# ET6801 register map
Vendor: ETMCU Inc.; File version: v0.0.1
CPU: CM7 r2p1, little endian, MPU, FPU, I-cache, D-cache, ITCM, DTCM, 4 interrupt priority bits
Registers are 32-bit, read-write, reset 0x0 unless marked. A register's access mark holds for its fields unless they carry their own. Offsets are from the block's base; [hi:lo] are bit positions; {n}, {i} and the like mark numbered series; <NAME> marks a mode.

## CRG — Provide an overview of the purpose and functionality of the peripheral: crg_cfg
Base 0x4040C000
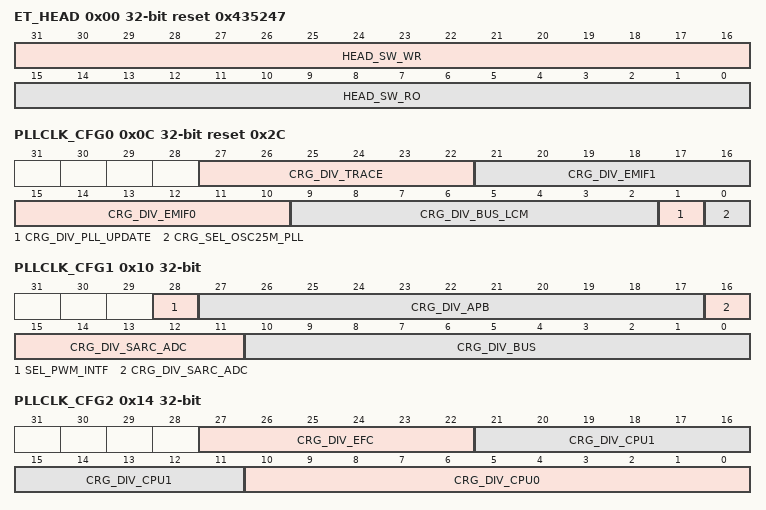
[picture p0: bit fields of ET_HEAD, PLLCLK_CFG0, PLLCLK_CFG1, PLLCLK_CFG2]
0x00 ET_HEAD reset 0x435247
  [31:16] HEAD_SW_WR — 软件测试读写寄存器，硬件无访问
  [15:0] HEAD_SW_RO ro — 软件只读上报寄存器，硬件无访问,CRG的ASICII 码表示
0x04 OSC25M_SEL
  [0] CRG_OSC25M_SEL — OSC25M时钟源选择信号： 1'b0：时钟源osc0_25m； 1'b1：时钟源osc1_25m；
0x08 PLLREF_CFG reset 0x2
  [2:0] CRG_PLL_REF_SEL — PLL参考时钟源选择信号： bit2: 默认0 1'b0：x025m和osc0/1_25m经过选择后的信号； 1'b1：pad_osc25m； bit1: 默认1 1'b0：x025m和osc025m经过选择后的信号； 1'b1：内部25m时钟源osc1_25m； bit0: 默认0 1'b0：时钟源xo25m； 1'b1：内部25m时钟源osc0_25m；
0x0C PLLCLK_CFG0 reset 0x2C
  [27:22] CRG_DIV_TRACE — Clk_bus到coresight工作时钟的分频系数 ， 6'd0：1分频 6'd1：2分频 6'd3：4分频 6'd5: 6 分频 6'd7：8分频 其他：正常使用时不使用该配置范围； 此配置值在"cfg_crg_div_pll_updata为1"且"bus时钟下计数到cfg_crg_div_bus_lcm值"时才更新；
  [21:16] CRG_DIV_EMIF1 — Clk_bus到emif1工作时钟的分频系数 ， 6'd0：1分频 6'd1：2分频 6'd2：3分频 6'd3：4分频 其他：正常使用时不使用该配置范围； 此配置值在"cfg_crg_div_pll_updata为1"且"bus时钟下计数到cfg_crg_div_bus_lcm值"时才更新；
  [15:10] CRG_DIV_EMIF0 — Clk_bus到emif0工作时钟的分频系数 ， 6'd0：1分频 6'd1：2分频 6'd2：3分频 6'd3：4分频 其他：正常使用时不使用该配置范围； 此配置值在"cfg_crg_div_pll_updata为1"且"bus时钟下计数到cfg_crg_div_bus_lcm值"时才更新；
  [9:2] CRG_DIV_BUS_LCM — bus_clk时钟源下各时钟（cpu0/1\cpu_apb0/1\apb\efc_flash\adc\emif\coresight）分频系数less common multipler（最小公倍数）配置，默认配置值+1 此配置默认为8'd11， 此配置值在"cfg_crg_div_pll_updata为1"且"bus时钟下计数到cfg_crg_div_bus_lcm值"时才更新；
  [1] CRG_DIV_PLL_UPDATE — PLL时钟分频系数更新指示信号 1'd0：不更新系数 1'd1：更新系数
  [0] CRG_SEL_OSC25M_PLL — OSC25M与PLL无毛刺切换的时钟选择信号： 1'd0: 选择osc25m 1'd1: 选择PLL 输出时钟 具体切换配置见CRG配置流程文档
0x10 PLLCLK_CFG1
  [28] SEL_PWM_INTF — pwm_interface接口时钟选择 1'b0:clk_bus 1'b1:clk_sys 400M
  [27:17] CRG_DIV_APB — Clk_bus到APB总线工作时钟分频系数 11'd0：1分频 11'd1：2分频 11'd3：4分频 11'd7：8分频 其他：正常使用时不使用该配置范围；当BUS时钟为200M时，配置为2分频，APB的时钟为100M 此配置值在"cfg_crg_div_pll_updata为1时才更新；
  [16:11] CRG_DIV_SARC_ADC — Clk_bus到到sarc adc工作时钟的分频系数 6'd0：1分频 6'd1：2分频 6'd2：3分频 6'd3：4分频 6'd4：5分频 6'd5-6'd63：正常使用时不使用该配置范围；当BUS时钟为200M时，配置为3分频，adc的时钟为66.6M 此配置值在"cfg_crg_div_pll_updata为1时才更新；
  [10:0] CRG_DIV_BUS — BUS总线的工作时钟分频系数 11'd0~11d'7：分别对应1分频~8分频 其他：正常使用时不使用该配置范围；pll为600M配置3分频，BUS的时钟为200M 其他：正常使用时不使用该配置范围； 此配置值在"cfg_crg_div_pll_updata为1时才更新；
0x14 PLLCLK_CFG2
  [27:22] CRG_DIV_EFC — Clk_bus到Efc flash工作时钟的分频系数 ， 6'd0：1分频 6'd1：2分频 6'd3：4分频 6'd5: 6 分频 6'd7：8分频 其他：正常使用时不使用该配置范围；当BUS时钟为200M时，配置为6分频，EFC FLASH的时钟为33.3M 此配置值在"cfg_crg_div_pll_updata为1"时才更新；
  [21:11] CRG_DIV_CPU1 — CPU1工作时钟分频系数， 11'd0~11d'7：分别对应1分频~8分频 6'd8-6'd63：正常使用时不使用该配置范围； PLL FOUT为600M
  [10:0] CRG_DIV_CPU0 — CPU0工作时钟分频系数， 11'd0~11d'7：分别对应1分频~8分频 6'd8-6'd63：正常使用时不使用该配置范围； PLL FOUT为600M时，配置为2分频 此配置值在"cfg_crg_div_pll_updata为1时才更新；
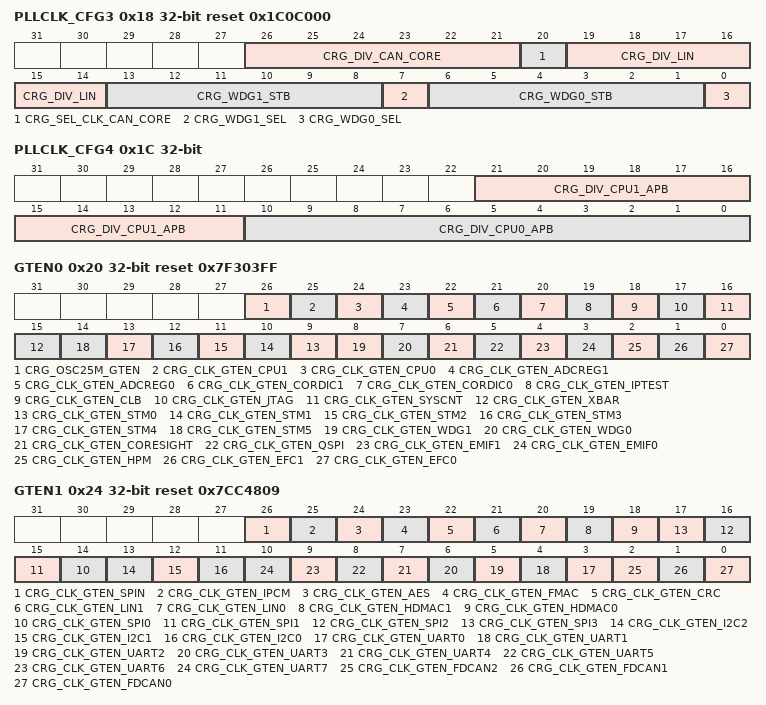
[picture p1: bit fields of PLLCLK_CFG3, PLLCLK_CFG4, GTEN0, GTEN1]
0x18 PLLCLK_CFG3 reset 0x1C0C000
  [26:21] CRG_DIV_CAN_CORE — Can core时钟分频系数 6'd4：5分频,由400M时钟分频到80M 6'd9：10分频,由600M时钟分频到60M 6'd14:：15分频，由600M时钟分频到40M(默认) 到60M 其他：正常使用时不使用该配置范围 此配置值在"cfg_crg_div_pll_updata为1"时才更新；
  [20] CRG_SEL_CLK_CAN_CORE — Can core时钟sel信号 1'd0：选择PLL的输出时钟 1'd1：选择pad输入的auxclk 默认选择PLL输出的400M时钟，静态切换
  [19:14] CRG_DIV_LIN — CLK_APB到LIN工作时钟分频系数 6'd0：1分频 6'd1：2分频 6'd3：4分频 6'd5：6分频 6'd7：8分频 6'd8-6'd63：正常使用时不使用该配置范围 ，默认4分频 此配置值在"cfg_crg_div_pll_updata为1时才更新；
  [13:8] CRG_WDG1_STB — wdg1的分频使能（clken），当wdg1选择APB时钟时， 支持对APB时钟进行1~64分频，作为数据使用， 6'd0：1分频使能 6'd1：2分频使能 6'd2：3分频使能 ...... 6'd63：64分频使能
  [7] CRG_WDG1_SEL — Wdg1时钟选择信号 1'd0：osc25m 1'd1：clk_apb1 默认选择osc25m_ana
  [6:1] CRG_WDG0_STB — wdg0的分频使能（clken），当wdg0选择APB时钟时， 支持对APB时钟进行1~64分频，作为数据使用， 6'd0：1分频使能 6'd1：2分频使能 6'd2：3分频使能 ...... 6'd63：64分频使能
  [0] CRG_WDG0_SEL — Wdg0时钟选择信号 1'd0：osc25m 1'd1：clk_apb1 默认选择osc25m_ana
0x1C PLLCLK_CFG4
  [21:11] CRG_DIV_CPU1_APB — CLK_CPU1到CPU1 APB接口配置时钟分频系数 11'd0~11d'7：分别对应1分频~8分频 11'd8-11'd2047：正常使用时不使用该配置范围；
  [10:0] CRG_DIV_CPU0_APB — CLK_CPU0到CPU0 APB接口配置时钟分频系数 11'd0~11d'7：分别对应1分频~8分频 11'd8-11'd2047：正常使用时不使用该配置范围；
0x20 GTEN0 reset 0x7F303FF
  [26] CRG_OSC25M_GTEN — OSC25M （osc0_25m_ana和osc1_25m_ana选择后的时钟）的时钟门控： 1：打开OSC25M时钟，0：关闭OSC25M时钟 在BootRom流程中，系统时钟切换到PLL时钟后，需要对osc25M时钟trim，trim时要关闭OSC25M时钟。 在BootRom流程中，系统时钟切换到PLL时钟后，关闭OSC0_25M与OSC1_25M选择后的时钟门控 此OSC25M时钟作用范围：EFUSE，JTAG_AUTH鉴权，WDT，SYSCNT，CPU, CRG展宽使用的OSC25M工作时钟
  [25] CRG_CLK_GTEN_CPU1 — cpu1的时钟门控配置 ，1表示开时钟，0表示关时钟
  [24] CRG_CLK_GTEN_CPU0 — cpu0的时钟门控配置 ，1表示开时钟，0表示关时钟
  [23] CRG_CLK_GTEN_ADCREG1 — cpu1 adcreg的时钟门控配置，1表示开时钟，0表示关时钟
  [22] CRG_CLK_GTEN_ADCREG0 — cpu0 adcreg的时钟门控配置，1表示开时钟，0表示关时钟
  [21] CRG_CLK_GTEN_CORDIC1 — cpu1 cordic的时钟门控配置，1表示开时钟，0表示关时钟
  [20] CRG_CLK_GTEN_CORDIC0 — cpu0 cordic的时钟门控配置，1表示开时钟，0表示关时钟
  [19] CRG_CLK_GTEN_IPTEST — IPTEST的时钟门控配置，1表示开时钟，0表示关时钟
  [18] CRG_CLK_GTEN_CLB — CLB的时钟门控配置，1表示开时钟，0表示关时钟
  [17] CRG_CLK_GTEN_JTAG — JTAG的时钟门控配置，1表示开时钟，0表示关时钟
  [16] CRG_CLK_GTEN_SYSCNT — SYSCNT的时钟门控配置，1表示开时钟，0表示关时钟
  [15] CRG_CLK_GTEN_XBAR — XBAR的时钟门控配置，1表示开时钟，0表示关时钟
  [n+9] CRG_CLK_GTEN_STM{n} (n=0..5) — STM{n}时钟门控配置，1表示开时钟，0表示关时钟
  [8] CRG_CLK_GTEN_WDG1 — WDG1的时钟门控配置，1表示开时钟，0表示关时钟
  [7] CRG_CLK_GTEN_WDG0 — WDG0的时钟门控配置，1表示开时钟，0表示关时钟
  [6] CRG_CLK_GTEN_CORESIGHT — CORE_SIGHT的时钟门控配置，1表示开时钟，0表示关时钟
  [5] CRG_CLK_GTEN_QSPI — QSPI的时钟门控配置，1表示开时钟，0表示关时钟
  [4] CRG_CLK_GTEN_EMIF1 — EMIF1的时钟门控配置，1表示开时钟，0表示关时钟
  [3] CRG_CLK_GTEN_EMIF0 — EMIF0的时钟门控配置，1表示开时钟，0表示关时钟
  [2] CRG_CLK_GTEN_HPM — HPM的时钟门控配置，1表示开时钟，0表示关时钟
  [1] CRG_CLK_GTEN_EFC1 — EFC1的时钟门控配置，1表示开时钟，0表示关时钟
  [0] CRG_CLK_GTEN_EFC0 — EFC0的时钟门控配置，1表示开时钟，0表示关时钟
0x24 GTEN1 reset 0x7CC4809
  [26] CRG_CLK_GTEN_SPIN — SPIN_LOCK的时钟门控配置，1表示开时钟，0表示关时钟
  [25] CRG_CLK_GTEN_IPCM — IPCM的时钟门控配置，1表示开时钟，0表示关时钟
  [24] CRG_CLK_GTEN_AES — AES的时钟门控配置，1表示开时钟，0表示关时钟
  [23] CRG_CLK_GTEN_FMAC — FMAC的时钟门控配置，1表示开时钟，0表示关时钟
  [22] CRG_CLK_GTEN_CRC — CRC的时钟门控配置，1表示开时钟，0表示关时钟
  [21] CRG_CLK_GTEN_LIN1 — LIN1的时钟门控配置，1表示开时钟，0表示关时钟
  [20] CRG_CLK_GTEN_LIN0 — LIN0的时钟门控配置，1表示开时钟，0表示关时钟
  [19] CRG_CLK_GTEN_HDMAC1 — HDMAC1的时钟门控配置，1表示开时钟，0表示关时钟
  [18] CRG_CLK_GTEN_HDMAC0 — HDMAC0的时钟门控配置，1表示开时钟，0表示关时钟
  [n+14] CRG_CLK_GTEN_SPI{n} (n=0..3) — SPI{n}的时钟门控配置，1表示开时钟，0表示关时钟
  [13] CRG_CLK_GTEN_I2C2 — I2C2(PMBUS)的时钟门控配置，1表示开时钟，0表示关时钟
  [12] CRG_CLK_GTEN_I2C1 — I2C1的时钟门控配置，1表示开时钟，0表示关时钟
  [11] CRG_CLK_GTEN_I2C0 — I2C0的时钟门控配置，1表示开时钟，0表示关时钟
  [n+3] CRG_CLK_GTEN_UART{n} (n=0..7) — UART{n}的时钟门控配置，1表示开时钟，0表示关时钟
  [2] CRG_CLK_GTEN_FDCAN2 — FDCAN2的时钟门控配置，1表示开时钟，0表示关时钟
  [1] CRG_CLK_GTEN_FDCAN1 — FDCAN1的时钟门控配置，1表示开时钟，0表示关时钟
  [0] CRG_CLK_GTEN_FDCAN0 — FDCAN0的时钟门控配置，1表示开时钟，0表示关时钟
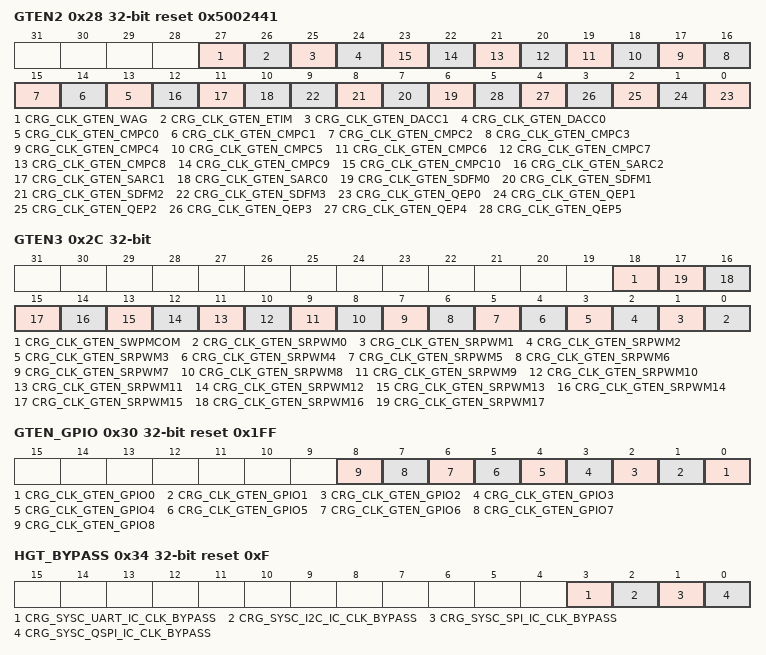
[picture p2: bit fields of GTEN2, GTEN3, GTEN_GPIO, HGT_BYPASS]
0x28 GTEN2 reset 0x5002441
  [27] CRG_CLK_GTEN_WAG — WAG的时钟门控配置，1表示开时钟，0表示关时钟
  [26] CRG_CLK_GTEN_ETIM — ETIM的时钟门控配置，1表示开时钟，0表示关时钟
  [25] CRG_CLK_GTEN_DACC1 — DACC1的时钟门控配置，1表示开时钟，0表示关时钟
  [24] CRG_CLK_GTEN_DACC0 — DACC0的时钟门控配置，1表示开时钟，0表示关时钟
  [n+13] CRG_CLK_GTEN_CMPC{n} (n=0..10) — CMPC{n}的时钟门控配置，1表示开时钟，0表示关时钟
  [12] CRG_CLK_GTEN_SARC2 — SARC2的时钟门控配置，1表示开时钟，0表示关时钟
  [11] CRG_CLK_GTEN_SARC1 — SARC1的时钟门控配置，1表示开时钟，0表示关时钟
  [10] CRG_CLK_GTEN_SARC0 — SARC0的时钟门控配置，1表示开时钟，0表示关时钟
  [n+6] CRG_CLK_GTEN_SDFM{n} (n=0..3) — SDFM{n}的时钟门控配置，1表示开时钟，0表示关时钟
  [n] CRG_CLK_GTEN_QEP{n} (n=0..5) — QEP{n}的时钟门控配置，1表示开时钟，0表示关时钟
0x2C GTEN3
  [18] CRG_CLK_GTEN_SWPMCOM — SPWM_COM的时钟门控配置，1表示开时钟，0表示关时钟
  [n] CRG_CLK_GTEN_SRPWM{n} (n=0..17) — SRPWM{n}的时钟门控配置，1表示开时钟，0表示关时钟
0x30 GTEN_GPIO reset 0x1FF
  [n] CRG_CLK_GTEN_GPIO{n} (n=0..8) — GPIO{n}的时钟门控配置，1表示开时钟，0表示关时钟
0x34 HGT_BYPASS reset 0xF
  [3] CRG_SYSC_UART_IC_CLK_BYPASS — uart硬件门控的bypass控制，6个 uart统一控制。1表示bypass硬件门控
  [2] CRG_SYSC_I2C_IC_CLK_BYPASS — I2c硬件门控的bypass控制，3个i2c统一控制。1表示bypass硬件门控
  [1] CRG_SYSC_SPI_IC_CLK_BYPASS — spi硬件门控的bypass控制。4个spi统一控制。1表示bypass硬件门控
  [0] CRG_SYSC_QSPI_IC_CLK_BYPASS — qspi硬件门控的bypass控制。1表示bypass硬件门控
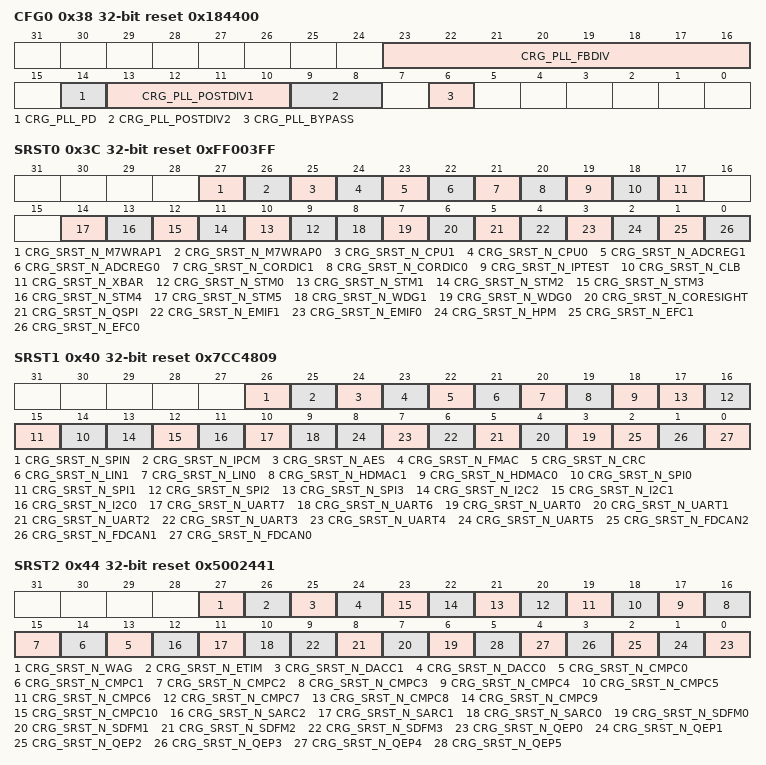
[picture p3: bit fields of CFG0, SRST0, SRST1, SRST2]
0x38 CFG0 reset 0x184400
  [23:16] CRG_PLL_FBDIV — PLL Feedback divide value。represent M M = M7*128+M6*64+M5*32+M4*16+M3*8+M2*4+M1*2+M0*1 defalt value = 24 clk_out = XIN * M/N/NO 1Mhz <= XIN/N <= 50Mhz 500Mhz <= clo_out * NO <= 1500 Mhz M >=2 , N >= 1
  [14] CRG_PLL_PD — Power down for PLL 0：work； 1：power down；
  [13:10] CRG_PLL_POSTDIV1 — PLL post divide 1 , represent N = N3*8+N2*4+N1*2+N0*1 Total post divide is POSTDIV1*POSTDIV2
  [9:8] CRG_PLL_POSTDIV2 — PLL post divide 2 , represent OD, NO=2^OD0+OD1*2 Total post divide is POSTDIV1*POSTDIV2
  [6] CRG_PLL_BYPASS — fref是否需要bypass到foutpostdiv。 0：pll正常输出； 1：fref bypass到foutpostdiv；
0x3C SRST0 reset 0xFF003FF
  [27] CRG_SRST_N_M7WRAP1 — m7_wrap1模块软复位配置，1表示不复位，0表示复位
  [26] CRG_SRST_N_M7WRAP0 — m7_wrap0模块软复位配置，1表示不复位，0表示复位
  [25] CRG_SRST_N_CPU1 — cpu1模块软复位配置，1表示不复位，0表示复位
  [24] CRG_SRST_N_CPU0 — cpu0模块软复位配置，1表示不复位，0表示复位
  [23] CRG_SRST_N_ADCREG1 — cpu1_adcreg模块软复位配置，1表示不复位，0表示复位
  [22] CRG_SRST_N_ADCREG0 — cpu0_adcreg模块软复位配置，1表示不复位，0表示复位
  [21] CRG_SRST_N_CORDIC1 — cpu1_cordic模块软复位配置，1表示不复位，0表示复位
  [20] CRG_SRST_N_CORDIC0 — cpu0_cordic模块软复位配置，1表示不复位，0表示复位
  [19] CRG_SRST_N_IPTEST — IPTEST的模块软复位配置，1表示不复位，0表示复位
  [18] CRG_SRST_N_CLB — CLB的模块软复位配置，1表示不复位，0表示复位
  [17] CRG_SRST_N_XBAR — XBAR的模块软复位配置，1表示不复位，0表示复位
  [n+9] CRG_SRST_N_STM{n} (n=0..5) — STM{n}模块软复位配置，1表示不复位，0表示复位
  [8] CRG_SRST_N_WDG1 — WDG1的模块软复位配置，1表示不复位，0表示复位
  [7] CRG_SRST_N_WDG0 — WDG0的模块软复位配置，1表示不复位，0表示复位
  [6] CRG_SRST_N_CORESIGHT — CORE_SIGHT的模块软复位配置，1表示不复位，0表示复位
  [5] CRG_SRST_N_QSPI — QSPI的模块软复位配置，1表示不复位，0表示复位
  [4] CRG_SRST_N_EMIF1 — EMIF1的模块软复位配置，1表示不复位，0表示复位
  [3] CRG_SRST_N_EMIF0 — EMIF0的模块软复位配置，1表示不复位，0表示复位
  [2] CRG_SRST_N_HPM — HPM的模块软复位配置，1表示不复位，0表示复位
  [1] CRG_SRST_N_EFC1 — EFC1的模块软复位配置，1表示不复位，0表示复位
  [0] CRG_SRST_N_EFC0 — EFC0的模块软复位配置，1表示不复位，0表示复位
0x40 SRST1 reset 0x7CC4809
  [26] CRG_SRST_N_SPIN — SPIN_LOCK的模块软复位配置，1表示不复位，0表示复位
  [25] CRG_SRST_N_IPCM — IPCM的模块软复位配置，1表示不复位，0表示复位
  [24] CRG_SRST_N_AES — AES的模块软复位配置，1表示不复位，0表示复位
  [23] CRG_SRST_N_FMAC — FMAC的模块软复位配置，1表示不复位，0表示复位
  [22] CRG_SRST_N_CRC — CRC的模块软复位配置，1表示不复位，0表示复位
  [21] CRG_SRST_N_LIN1 — LIN1的模块软复位配置，1表示不复位，0表示复位
  [20] CRG_SRST_N_LIN0 — LIN0的模块软复位配置，1表示不复位，0表示复位
  [19] CRG_SRST_N_HDMAC1 — HDMAC1的模块软复位配置，1表示不复位，0表示复位
  [18] CRG_SRST_N_HDMAC0 — HDMAC0的模块软复位配置，1表示不复位，0表示复位
  [n+14] CRG_SRST_N_SPI{n} (n=0..3) — SPI{n}的模块软复位配置，1表示不复位，0表示复位
  [13] CRG_SRST_N_I2C2 — I2C2(PMBUS)的模块软复位配置，1表示不复位，0表示复位
  [12] CRG_SRST_N_I2C1 — I2C1的模块软复位配置，1表示不复位，0表示复位
  [11] CRG_SRST_N_I2C0 — I2C0的模块软复位配置，1表示不复位，0表示复位
  [10] CRG_SRST_N_UART7 — UART7模块软复位配置，1表示不复位，0表示复位
  [9] CRG_SRST_N_UART6 — UART6模块软复位配置，1表示不复位，0表示复位
  [n+3] CRG_SRST_N_UART{n} (n=0..5) — UART{n}的模块软复位配置，1表示不复位，0表示复位
  [2] CRG_SRST_N_FDCAN2 — FDCAN2的模块软复位配置，1表示不复位，0表示复位
  [1] CRG_SRST_N_FDCAN1 — FDCAN1的模块软复位配置，1表示不复位，0表示复位
  [0] CRG_SRST_N_FDCAN0 — FDCAN0的模块软复位配置，1表示不复位，0表示复位
0x44 SRST2 reset 0x5002441
  [27] CRG_SRST_N_WAG — WAG的模块软复位配置，1表示不复位，0表示复位
  [26] CRG_SRST_N_ETIM — ETIM的模块软复位配置，1表示不复位，0表示复位
  [25] CRG_SRST_N_DACC1 — DACC1的模块软复位配置，1表示不复位，0表示复位
  [24] CRG_SRST_N_DACC0 — DACC0的模块软复位配置，1表示不复位，0表示复位
  [n+13] CRG_SRST_N_CMPC{n} (n=0..10) — CMPC{n}的模块软复位配置，1表示不复位，0表示复位
  [12] CRG_SRST_N_SARC2 — SARC2的模块软复位配置，1表示不复位，0表示复位
  [11] CRG_SRST_N_SARC1 — SARC1的模块软复位配置，1表示不复位，0表示复位
  [10] CRG_SRST_N_SARC0 — SARC0的模块软复位配置，1表示不复位，0表示复位
  [n+6] CRG_SRST_N_SDFM{n} (n=0..3) — SDFM{n}的模块软复位配置，1表示不复位，0表示复位
  [n] CRG_SRST_N_QEP{n} (n=0..5) — QEP{n}的模块软复位配置，1表示不复位，0表示复位
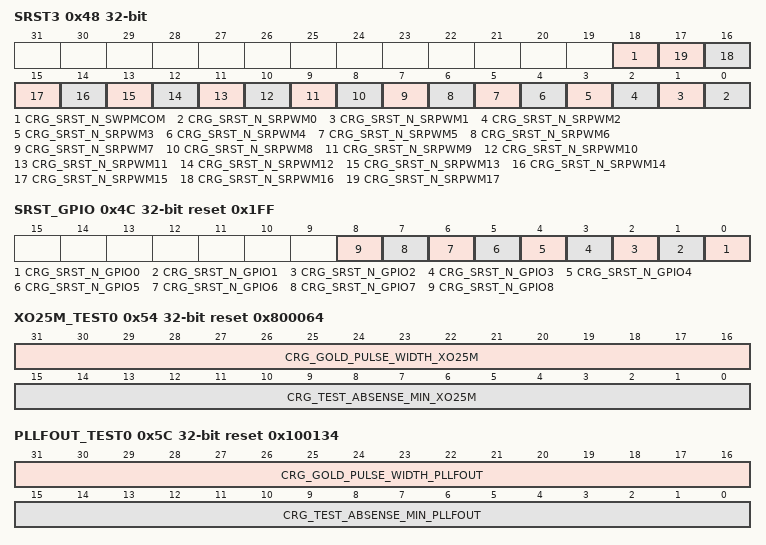
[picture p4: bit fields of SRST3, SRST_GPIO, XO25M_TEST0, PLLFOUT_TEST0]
0x48 SRST3
  [18] CRG_SRST_N_SWPMCOM — SPWM_COM的模块软复位配置，1表示不复位，0表示复位
  [n] CRG_SRST_N_SRPWM{n} (n=0..17) — SRPWM{n}的模块软复位配置，1表示不复位，0表示复位
0x4C SRST_GPIO reset 0x1FF
  [n] CRG_SRST_N_GPIO{n} (n=0..8) — GPIO{n}的模块软复位配置，1表示不复位，0表示复位
0x50 CLK_TEST_EN reset 0x1
  [0] CRG_CLK_TEST_EN — 时钟检测使能信号，1表示使能时钟检测，0表示不使能； 默认打开时钟检测； 该en信号控制以下时钟检测功能模块： osc0_25mosc1_25m 时钟丢失检测， osc1_25mosc0_25m 时钟丢失检测， osc1_25mxo25m 时钟丢失检测， xo25mosc1_25m 时钟丢失检测， osc1_25mpll_fout 时钟丢失检测， 注意： 以上这些检测模块在配置参数修改前，必须先将该en信号关闭，参数配置修改完成后再打开该en信号。
0x54 XO25M_TEST0 reset 0x800064
  [31:16] CRG_GOLD_PULSE_WIDTH_XO25M — OSC25M时钟检测XO25M时钟。检测宽度配置 默认配置16'd128；
  [15:0] CRG_TEST_ABSENSE_MIN_XO25M — OSC25M时钟检测XO25M时钟。检测宽度内，最小时钟周期数配置。当计数小于该配置值时，上报时钟丢失告警 默认配置16'd100；
0x58 XO25M_TEST1 reset 0x9C
  [15:0] CRG_TEST_ABSENSE_MAX_XO25M — OSC25M时钟检测XO25M时钟。检测宽度内，最大时钟周期数配置。当计数大于该配置值时，上报时钟丢失告警 默认配置16'd156；
0x5C PLLFOUT_TEST0 reset 0x100134
  [31:16] CRG_GOLD_PULSE_WIDTH_PLLFOUT — OSC25M时钟检测PLLFOUT（PLL 输出的600M）时钟。检测宽度配置 默认配置16'd16
  [15:0] CRG_TEST_ABSENSE_MIN_PLLFOUT — OSC25M时钟检测PLLFOUT（PLL 输出的600M）时钟。检测宽度内，最小时钟周期数配置。当计数小于该配置值时，上报时钟丢失告警 默认配置8'd100；默认配置16'd308；
0x60 PLLFOUT_TEST1 reset 0x1CC
  [15:0] CRG_TEST_ABSENSE_MAX_PLLFOUT — OSC25M时钟检测PLL1FOUT（PLL 输出的600M）时钟。检测宽度内，最大时钟周期数配置。当计数大于该配置值时，上报时钟丢失告警 默认配置16'd460；
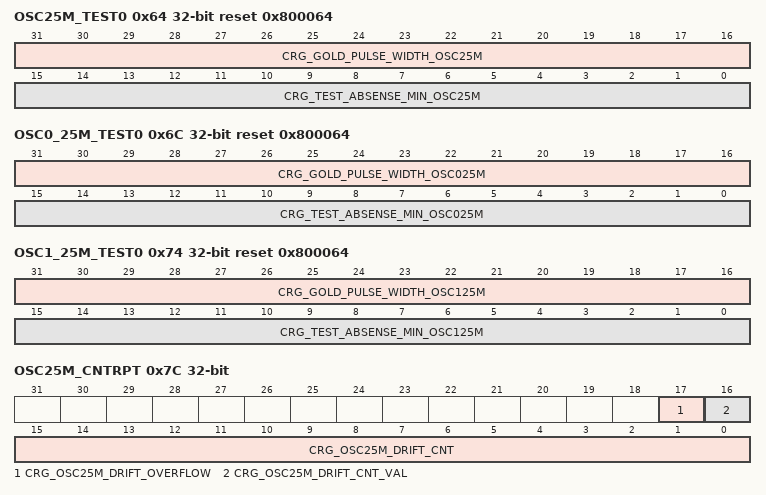
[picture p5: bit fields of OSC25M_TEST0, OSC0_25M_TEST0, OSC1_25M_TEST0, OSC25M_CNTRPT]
0x64 OSC25M_TEST0 reset 0x800064
  [31:16] CRG_GOLD_PULSE_WIDTH_OSC25M — XO25M时钟检测OSC1_25M时钟。检测宽度配置， 默认配置16'd128；
  [15:0] CRG_TEST_ABSENSE_MIN_OSC25M — XO25M时钟检测OSC25M时钟。检测宽度内，最小时钟周期数配置。当计数小于该配置值时，上报时钟丢失告警 默认配置16'd100；
0x68 OSC25M_TEST1 reset 0x9C
  [15:0] CRG_TEST_ABSENSE_MAX_OSC25M — XO25M时钟检测OSC1_25M时钟。检测宽度内，最大时钟周期数配置。当计数大于该配置值时，上报时钟丢失告警 默认配置16'd156；
0x6C OSC0_25M_TEST0 reset 0x800064
  [31:16] CRG_GOLD_PULSE_WIDTH_OSC025M — OSC1_25M时钟检测OSC0_25M时钟。检测宽度配置， 默认配置16'd128；
  [15:0] CRG_TEST_ABSENSE_MIN_OSC025M — OSC1_25M时钟检测OSC0_25M时钟。检测宽度内，最小时钟周期数配置。当计数小于该配置值时，上报时钟丢失告警 默认配置16'd100；
0x70 OSC0_25M_TEST1 reset 0x9C
  [15:0] CRG_TEST_ABSENSE_MAX_OSC025M — OSC1_25M时钟检测OSC0_25M时钟。检测宽度内，最大时钟周期数配置。当计数大于该配置值时，上报时钟丢失告警 默认配置16'd156；
0x74 OSC1_25M_TEST0 reset 0x800064
  [31:16] CRG_GOLD_PULSE_WIDTH_OSC125M — OSC0_25M时钟检测OSC1_25M时钟。检测宽度配置， 默认配置16'd128；
  [15:0] CRG_TEST_ABSENSE_MIN_OSC125M — XSC1_25M时钟检测OSC0_25M时钟。检测宽度内，最小时钟周期数配置。当计数小于该配置值时，上报时钟丢失告警 默认配置16'd100；
0x78 OSC1_25M_TEST1 reset 0x9C
  [15:0] CRG_TEST_ABSENSE_MAX_OSC125M — OSC0_25M时钟检测OSC1_25M时钟。检测宽度内，最大时钟周期数配置。当计数大于该配置值时，上报时钟丢失告警 默认配置16'd156；
0x7C OSC25M_CNTRPT ro
  [17] CRG_OSC25M_DRIFT_OVERFLOW — XO25M检查OSC25M频偏的计数值有效指示，为1表示计数溢出过。
  [16] CRG_OSC25M_DRIFT_CNT_VAL — XO25M检查OSC25M频偏的计数值有效指示，为1表示计数值有效
  [15:0] CRG_OSC25M_DRIFT_CNT — XO25M检查OSC25M频偏的计数值，31bit计数值； 当计数溢出时，该16bit保持最大值；
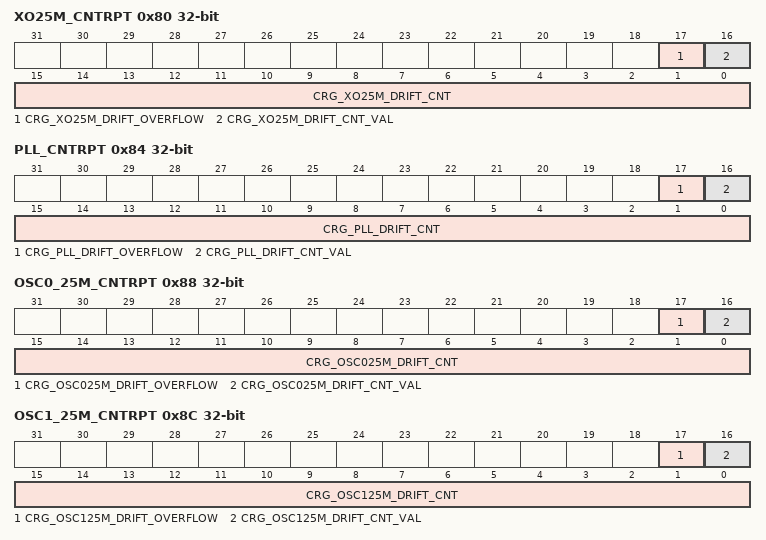
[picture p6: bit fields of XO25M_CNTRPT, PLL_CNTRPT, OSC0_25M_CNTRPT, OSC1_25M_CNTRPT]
0x80 XO25M_CNTRPT ro
  [17] CRG_XO25M_DRIFT_OVERFLOW — OSC25M检查XO25M频偏的计数值有效指示，为1表示计数溢出过。
  [16] CRG_XO25M_DRIFT_CNT_VAL — OSC25M检查XO25M频偏的计数值有效指示，为1表示计数值有效
  [15:0] CRG_XO25M_DRIFT_CNT — OSC25M检查XO25M频偏的计数值，31bit计数值； 当计数溢出时，该16bit保持最大值；
0x84 PLL_CNTRPT ro
  [17] CRG_PLL_DRIFT_OVERFLOW — OSC25M检查PLL频偏的计数值有效指示，为1表示计数溢出过。
  [16] CRG_PLL_DRIFT_CNT_VAL — OSC25M检查PLL频偏的计数值有效指示，为1表示计数值有效
  [15:0] CRG_PLL_DRIFT_CNT — OSC25M检查PLL频偏的计数值，31bit计数值； 当计数溢出时，该16bit保持最大值；
0x88 OSC0_25M_CNTRPT ro
  [17] CRG_OSC025M_DRIFT_OVERFLOW — OSC1_25M检查OSC0_25M频偏的计数值有效指示，为1表示计数溢出过。
  [16] CRG_OSC025M_DRIFT_CNT_VAL — OSC1_25M检查OSC0_25M频偏的计数值有效指示，为1表示计数值有效
  [15:0] CRG_OSC025M_DRIFT_CNT — OSC1_25M检查OSC0_25M频偏的计数值，31bit计数值； 当计数溢出时，该16bit保持最大值；
0x8C OSC1_25M_CNTRPT ro
  [17] CRG_OSC125M_DRIFT_OVERFLOW — OSC0_25M检查OSC1_25M频偏的计数值有效指示，为1表示计数溢出过。
  [16] CRG_OSC125M_DRIFT_CNT_VAL — OSC0_25M检查OSC1_25M频偏的计数值有效指示，为1表示计数值有效
  [15:0] CRG_OSC125M_DRIFT_CNT — OSC0_25M检查OSC1_25M频偏的计数值，31bit计数值； 当计数溢出时，该16bit保持最大值；
0x90 OSCCAL_EN
  [0] CRG_OSCCAL_EN — osc25m校正使能信号，用于启动osc25m校正
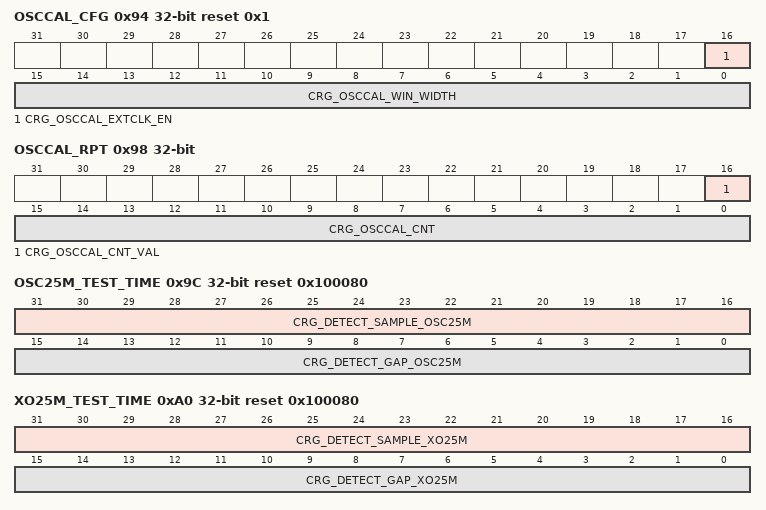
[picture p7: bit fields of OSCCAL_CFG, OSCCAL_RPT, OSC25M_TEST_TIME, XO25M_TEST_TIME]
0x94 OSCCAL_CFG reset 0x1
  [16] CRG_OSCCAL_EXTCLK_EN — osc25m校正时的高精度时钟选择。0表示选择xo32.768k，1表示选择io输入时钟
  [15:0] CRG_OSCCAL_WIN_WIDTH — osc25m校正计数窗口，高精度参考时钟的周期数配置，默认配置为2个周期 16'd0：1个周期； 16'd 1：2个周期； 16'd 2：3个周期； ......
0x98 OSCCAL_RPT ro
  [16] CRG_OSCCAL_CNT_VAL — osc25m校正计数有效指示信号，该信号为高时counter有效，读清零
  [15:0] CRG_OSCCAL_CNT — osc25m校正计数counter值
0x9C OSC25M_TEST_TIME reset 0x100080
  [31:16] CRG_DETECT_SAMPLE_OSC25M — XO25M时钟检测OSC1_25M时钟。检测采样点时间配置， 默认配置16'h10； 注意：如果用户需要修改此配置值，要求修改值必须大于16'h10；
  [15:0] CRG_DETECT_GAP_OSC25M — XO25M时钟检测OSC1_25M时钟。检测间隔配置， 默认配置16'h80； 注意：如果用户需要修改此配置值，要求修改值必须大于16'h80；
0xA0 XO25M_TEST_TIME reset 0x100080
  [31:16] CRG_DETECT_SAMPLE_XO25M — OSC1_25M时钟检测XO25M时钟。检测采样点时间配置， 默认配置16'h10； 注意：如果用户需要修改此配置值，要求修改值必须大于16'h10；
  [15:0] CRG_DETECT_GAP_XO25M — OSC1_25M时钟检测XO25M时钟。检测间隔配置， 默认配置16'h80； 注意：如果用户需要修改此配置值，要求修改值必须大于16'h80；
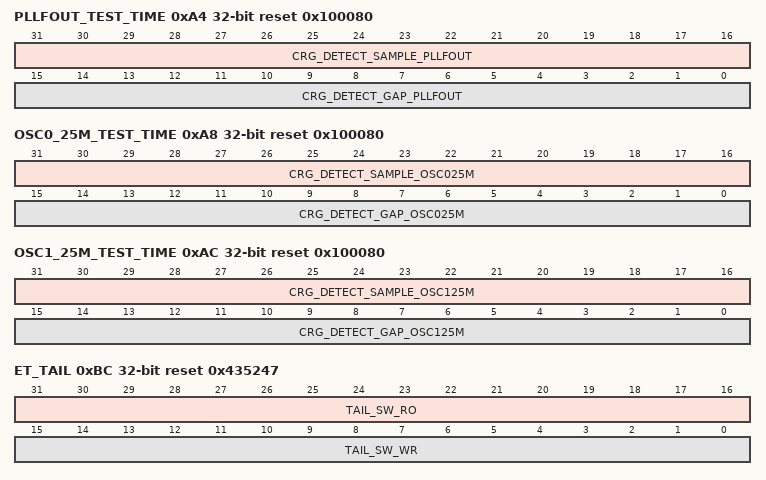
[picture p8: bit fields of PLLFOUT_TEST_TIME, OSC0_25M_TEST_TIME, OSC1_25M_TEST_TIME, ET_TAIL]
0xA4 PLLFOUT_TEST_TIME reset 0x100080
  [31:16] CRG_DETECT_SAMPLE_PLLFOUT — OSC25M时钟检测PLLFOUT时钟。检测采样点时间配置， 默认配置16'h10； 注意：如果用户需要修改此配置值，要求修改值必须大于16'h10；
  [15:0] CRG_DETECT_GAP_PLLFOUT — OSC25M时钟检测PLLFOUT时钟。检测间隔配置， 默认配置16'h80； 注意：如果用户需要修改此配置值，要求修改值必须大于16'h80；
0xA8 OSC0_25M_TEST_TIME reset 0x100080
  [31:16] CRG_DETECT_SAMPLE_OSC025M — OSC1_25M时钟检测OSC0_25M时钟。检测采样点时间配置， 默认配置16'h10； 注意：如果用户需要修改此配置值，要求修改值必须大于16'h10；
  [15:0] CRG_DETECT_GAP_OSC025M — OSC1_25M时钟检测OSC0_25M时钟。检测间隔配置， 默认配置16'h80； 注意：如果用户需要修改此配置值，要求修改值必须大于16'h80；
0xAC OSC1_25M_TEST_TIME reset 0x100080
  [31:16] CRG_DETECT_SAMPLE_OSC125M — OSC0_25M时钟检测OSC1_25M时钟。检测采样点时间配置， 默认配置16'h10； 注意：如果用户需要修改此配置值，要求修改值必须大于16'h10；
  [15:0] CRG_DETECT_GAP_OSC125M — OSC0_25M时钟检测OSC1_25M时钟。检测间隔配置， 默认配置16'h80； 注意：如果用户需要修改此配置值，要求修改值必须大于16'h80；
0xB0 DEBUG ro
  [31:0] CRG_DEBUG — Debug信号： Bit7-bit0： Ana_por_fg Osc25m_por Rstn_por Osc25m_hrstn Osc25m_grstn Osc25m_wdg0 Osc25m_wdg1 Osc25m_cpu0_grstn; Bit15-bit8： sysc_por_fg_rst_n Osc25m_cpu1_grstn; ioc_flt_rstn Ioc_presetn Hrstn_sources Hrstn_chip Rstn_crg Rstn_hrd; Bit27-bit16: Osc25m_bps_n, Por_bps_n, stb_wdg1_clken, stb_wdg0_clken, dft_pll_bypass, dft_sel_osc25m_pll hrstn_fg, a2d_por1p1, A2d_pmu_vdda_ok, Crg_dac_latch_output, 1'd0, 1'd0, Bit31-bit28：4'd0；
0xB4 KEY_CTRL reset 0x12345678
  [31:0] SW_ACCESS_KEY — 软件读写控制权限的KEY设置，只有KEY设置为0x7879a8a9，驱动软件才能访问相关软件可以访问的寄存器；否则无法配置CRG 相关寄存器,包括参考时钟选择，PLL配置，时钟切换，CPU，BUS，APB，EFC，ADC ,CAN相关的时钟选择及分频配置，模块的时钟软门控，模块软复位；
0xB8 CLK_OUT_TST reset 0x1
  [1:0] XCLK_OUT_SEL — xclk_out输出选择； 'd0：ana_xo25m 'd1：clk_pll_fout_div16_ng 'd2：osc1_25m_ana 'd3：osc0_25m_ana
0xBC ET_TAIL reset 0x435247
  [31:16] TAIL_SW_RO ro — 软件只读上报寄存器，硬件无访问
  [15:0] TAIL_SW_WR — 软件测试读写寄存器，硬件无访问,CRG的ASICII 码表示
